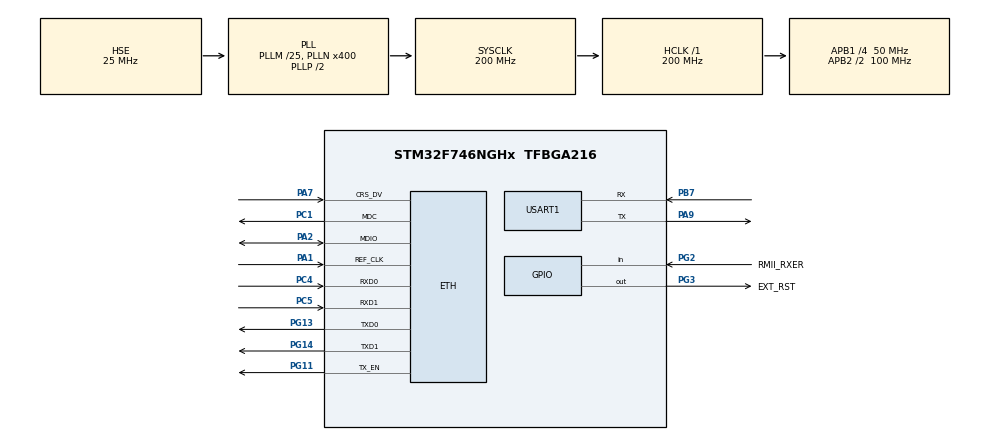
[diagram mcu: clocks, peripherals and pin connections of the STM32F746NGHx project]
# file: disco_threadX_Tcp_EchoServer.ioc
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ETH.MACAddr=00\:80\:E1\:00\:00\:01
ETH.MediaInterface=HAL_ETH_RMII_MODE
Mcu.Family=STM32F7
Mcu.Name=STM32F746NGHx
Mcu.Package=TFBGA216
NVIC.ETH_IRQn=true\:0\:0\:false\:false\:true\:false\:true\:true\:true
NVIC.ETH_WKUP_IRQn=true\:0\:0\:false\:false\:true\:false\:true\:true\:true
NVIC.PriorityGroup=NVIC_PRIORITYGROUP_4
NVIC.TIM6_DAC_IRQn=true\:15\:0\:false\:false\:true\:false\:false\:true\:true
NVIC.TimeBase=TIM6_DAC_IRQn
NVIC.TimeBaseIP=TIM6
PA1.Mode=RMII
PA1.Signal=ETH_REF_CLK
PA13.Mode=Serial_Wire
PA13.Signal=SYS_JTMS-SWDIO
PA14.Mode=Serial_Wire
PA14.Signal=SYS_JTCK-SWCLK
PA2.Mode=RMII
PA2.Signal=ETH_MDIO
PA7.Mode=RMII
PA7.Signal=ETH_CRS_DV
PA9.Mode=Asynchronous
PA9.Signal=USART1_TX
PB7.Mode=Asynchronous
PB7.Signal=USART1_RX
PC1.Mode=RMII
PC1.Signal=ETH_MDC
PC14/OSC32_IN.Mode=LSE-External-Oscillator
PC14/OSC32_IN.Signal=RCC_OSC32_IN
PC15/OSC32_OUT.Mode=LSE-External-Oscillator
PC15/OSC32_OUT.Signal=RCC_OSC32_OUT
PC4.Mode=RMII
PC4.Signal=ETH_RXD0
PC5.Mode=RMII
PC5.Signal=ETH_RXD1
PG11.Mode=RMII
PG11.Signal=ETH_TX_EN
PG13.Mode=RMII
PG13.Signal=ETH_TXD0
PG14.Mode=RMII
PG14.Signal=ETH_TXD1
PG2.GPIO_Label=RMII_RXER
PG2.Signal=GPIO_Input
PG3.GPIO_Label=EXT_RST
PG3.Signal=GPIO_Output
PH0/OSC_IN.Mode=HSE-External-Oscillator
PH0/OSC_IN.Signal=RCC_OSC_IN
PH1/OSC_OUT.Mode=HSE-External-Oscillator
PH1/OSC_OUT.Signal=RCC_OSC_OUT
ProjectManager.HeapSize=0x200
ProjectManager.StackSize=0x400
ProjectManager.TargetToolchain=STM32CubeIDE
RCC.AHBFreq_Value=200000000
RCC.APB1CLKDivider=RCC_HCLK_DIV4
RCC.APB1Freq_Value=50000000
RCC.APB1TimFreq_Value=100000000
RCC.APB2CLKDivider=RCC_HCLK_DIV2
RCC.APB2Freq_Value=100000000
RCC.APB2TimFreq_Value=200000000
RCC.CortexFreq_Value=200000000
RCC.HCLKFreq_Value=200000000
RCC.HSE_VALUE=25000000
RCC.HSI_VALUE=16000000
RCC.PLL48CLockSelection=RCC_CLK48SOURCE_PLLSAIP
RCC.PLLI2SN=100
RCC.PLLM=25
RCC.PLLN=400
RCC.PLLQ=9
RCC.PLLSAIN=384
RCC.PLLSAIP=RCC_PLLSAIP_DIV8
RCC.PLLSAIR=5
RCC.PLLSAIRDiv=RCC_PLLSAIDIVR_8
RCC.PLLSourceVirtual=RCC_PLLSOURCE_HSE
RCC.SDMMCClockSelection=RCC_SDMMC1CLKSOURCE_CLK48
RCC.SYSCLKFreq_VALUE=200000000
RCC.SYSCLKSource=RCC_SYSCLKSOURCE_PLLCLK
RCC.USBFreq_Value=48000000
RCC.VCOOutputFreq_Value=400000000
STMicroelectronics.X-CUBE-AZRTOS-F7.1.1.0.InterfacesCcNetworkJjEthernetOoInterface=true
STMicroelectronics.X-CUBE-AZRTOS-F7.1.1.0.InterfacesCcNetworkJjEthernetOoPhyOoInterface=LAN8742IiPhyIiInterface
STMicroelectronics.X-CUBE-AZRTOS-F7.1.1.0.NX_ENABLE_INTERFACE_CAPABILITY=true
STMicroelectronics.X-CUBE-AZRTOS-F7.1.1.0.NetXDuoCcNetworkJjNetXDuoJjAddonsOoDHCPOoClient=true
STMicroelectronics.X-CUBE-AZRTOS-F7.1.1.0.NetXDuoCcNetworkJjNetXDuoJjNXOoCore=true
STMicroelectronics.X-CUBE-AZRTOS-F7.1.1.0.STM32CubeIiBSPIiComponentsCcBoardOoPartJjETHPhyJjLAN8742=true
STMicroelectronics.X-CUBE-AZRTOS-F7.1.1.0.ThreadXCcRTOSJjThreadXJjCore=true
STMicroelectronics.X-CUBE-AZRTOS-F7.1.1.0_IsAnAzureRtosMw=true
USART1.VirtualMode-Asynchronous=VM_ASYNC
VP_CRC_VS_CRC.Mode=CRC_Activate
VP_STMicroelectronics.X-CUBE-AZRTOS-F7_VS_BoardOoPartJjSTM32CubeIiBSPIiComponents_1.1.0_1.1.0.Mode=BoardOoPartJjSTM32CubeIiBSPIiComponents
VP_STMicroelectronics.X-CUBE-AZRTOS-F7_VS_NetworkJjInterfaces_2.1.0_1.1.0.Mode=NetworkJjInterfaces
VP_STMicroelectronics.X-CUBE-AZRTOS-F7_VS_NetworkJjNetXDuo_6.1.10_1.1.0.Mode=NetworkJjNetXDuo
VP_STMicroelectronics.X-CUBE-AZRTOS-F7_VS_RTOSJjThreadX_6.1.10_1.1.0.Mode=RTOSJjThreadX
VP_SYS_VS_tim6.Mode=TIM6
board=STM32F746G-DISCO

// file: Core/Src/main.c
/* USER CODE BEGIN Header */
/**
  ******************************************************************************
  * @file           : main.c
  * @brief          : Main program body
  ******************************************************************************
  * @attention
  *
  * Copyright (c) 2025 STMicroelectronics.
  * All rights reserved.
  *
  * This software is licensed under terms that can be found in the LICENSE file
  * in the root directory of this software component.
  * If no LICENSE file comes with this software, it is provided AS-IS.
  *
  ******************************************************************************
  */
/* USER CODE END Header */
#include "app_threadx.h"
#include "main.h"
#include "string.h"

/* USER CODE BEGIN Includes */
#include <stdio.h>

/* USER CODE END Includes */

ETH_TxPacketConfig TxConfig;
ETH_DMADescTypeDef  DMARxDscrTab[ETH_RX_DESC_CNT]; /* Ethernet Rx DMA Descriptors */
ETH_DMADescTypeDef  DMATxDscrTab[ETH_TX_DESC_CNT]; /* Ethernet Tx DMA Descriptors */

CRC_HandleTypeDef hcrc;

ETH_HandleTypeDef heth;

UART_HandleTypeDef huart1;

void SystemClock_Config(void);
static void MX_GPIO_Init(void);
static void MX_USART1_UART_Init(void);
static void MX_CRC_Init(void);
static void MX_ETH_Init(void);

/* USER CODE BEGIN 0 */
int _write(int file, char *ptr, int len) {
    for (int i = 0; i < len; i++) {
        HAL_UART_Transmit(&huart1, (uint8_t *)&ptr[i], 1, HAL_MAX_DELAY);
    }
    return len;
}

/* USER CODE END 0 */

int main(void)
{

  /* MCU Configuration--------------------------------------------------------*/

  /* Reset of all peripherals, Initializes the Flash interface and the Systick. */
  HAL_Init();

  /* Configure the system clock */
  SystemClock_Config();

  /* Initialize all configured peripherals */
  MX_GPIO_Init();
  MX_USART1_UART_Init();
  MX_CRC_Init();
  MX_ETH_Init();
  /* USER CODE BEGIN 2 */
  setvbuf(stdout, NULL, _IONBF, 0);

  /* USER CODE END 2 */

  MX_ThreadX_Init();

  /* We should never get here as control is now taken by the scheduler */

  /* Infinite loop */
  while (1)
  {

  }
}

void SystemClock_Config(void)
{
  RCC_OscInitTypeDef RCC_OscInitStruct = {0};
  RCC_ClkInitTypeDef RCC_ClkInitStruct = {0};

  /** Configure LSE Drive Capability
  */
  HAL_PWR_EnableBkUpAccess();

  /** Configure the main internal regulator output voltage
  */
  __HAL_RCC_PWR_CLK_ENABLE();
  __HAL_PWR_VOLTAGESCALING_CONFIG(PWR_REGULATOR_VOLTAGE_SCALE1);

  /** Initializes the RCC Oscillators according to the specified parameters
  * in the RCC_OscInitTypeDef structure.
  */
  RCC_OscInitStruct.OscillatorType = RCC_OSCILLATORTYPE_HSE;
  RCC_OscInitStruct.HSEState = RCC_HSE_ON;
  RCC_OscInitStruct.PLL.PLLState = RCC_PLL_ON;
  RCC_OscInitStruct.PLL.PLLSource = RCC_PLLSOURCE_HSE;
  RCC_OscInitStruct.PLL.PLLM = 25;
  RCC_OscInitStruct.PLL.PLLN = 400;
  RCC_OscInitStruct.PLL.PLLP = RCC_PLLP_DIV2;
  RCC_OscInitStruct.PLL.PLLQ = 9;
  if (HAL_RCC_OscConfig(&RCC_OscInitStruct) != HAL_OK)
  {
    Error_Handler();
  }

  /** Activate the Over-Drive mode
  */
  if (HAL_PWREx_EnableOverDrive() != HAL_OK)
  {
    Error_Handler();
  }

  /** Initializes the CPU, AHB and APB buses clocks
  */
  RCC_ClkInitStruct.ClockType = RCC_CLOCKTYPE_HCLK|RCC_CLOCKTYPE_SYSCLK
                              |RCC_CLOCKTYPE_PCLK1|RCC_CLOCKTYPE_PCLK2;
  RCC_ClkInitStruct.SYSCLKSource = RCC_SYSCLKSOURCE_PLLCLK;
  RCC_ClkInitStruct.AHBCLKDivider = RCC_SYSCLK_DIV1;
  RCC_ClkInitStruct.APB1CLKDivider = RCC_HCLK_DIV4;
  RCC_ClkInitStruct.APB2CLKDivider = RCC_HCLK_DIV2;

  if (HAL_RCC_ClockConfig(&RCC_ClkInitStruct, FLASH_LATENCY_6) != HAL_OK)
  {
    Error_Handler();
  }
}

static void MX_CRC_Init(void)
{

  hcrc.Instance = CRC;
  hcrc.Init.DefaultPolynomialUse = DEFAULT_POLYNOMIAL_ENABLE;
  hcrc.Init.DefaultInitValueUse = DEFAULT_INIT_VALUE_ENABLE;
  hcrc.Init.InputDataInversionMode = CRC_INPUTDATA_INVERSION_NONE;
  hcrc.Init.OutputDataInversionMode = CRC_OUTPUTDATA_INVERSION_DISABLE;
  hcrc.InputDataFormat = CRC_INPUTDATA_FORMAT_BYTES;
  if (HAL_CRC_Init(&hcrc) != HAL_OK)
  {
    Error_Handler();
  }

}

static void MX_ETH_Init(void)
{

   static uint8_t MACAddr[6];

  heth.Instance = ETH;
  MACAddr[0] = 0x00;
  MACAddr[1] = 0x80;
  MACAddr[2] = 0xE1;
  MACAddr[3] = 0x00;
  MACAddr[4] = 0x00;
  MACAddr[5] = 0x01;
  heth.Init.MACAddr = &MACAddr[0];
  heth.Init.MediaInterface = HAL_ETH_RMII_MODE;
  heth.Init.TxDesc = DMATxDscrTab;
  heth.Init.RxDesc = DMARxDscrTab;
  heth.Init.RxBuffLen = 1536;

  if (HAL_ETH_Init(&heth) != HAL_OK)
  {
    Error_Handler();
  }

  memset(&TxConfig, 0 , sizeof(ETH_TxPacketConfig));
  TxConfig.Attributes = ETH_TX_PACKETS_FEATURES_CSUM | ETH_TX_PACKETS_FEATURES_CRCPAD;
  TxConfig.ChecksumCtrl = ETH_CHECKSUM_IPHDR_PAYLOAD_INSERT_PHDR_CALC;
  TxConfig.CRCPadCtrl = ETH_CRC_PAD_INSERT;

}

static void MX_USART1_UART_Init(void)
{

  huart1.Instance = USART1;
  huart1.Init.BaudRate = 115200;
  huart1.Init.WordLength = UART_WORDLENGTH_8B;
  huart1.Init.StopBits = UART_STOPBITS_1;
  huart1.Init.Parity = UART_PARITY_NONE;
  huart1.Init.Mode = UART_MODE_TX_RX;
  huart1.Init.HwFlowCtl = UART_HWCONTROL_NONE;
  huart1.Init.OverSampling = UART_OVERSAMPLING_16;
  huart1.Init.OneBitSampling = UART_ONE_BIT_SAMPLE_DISABLE;
  huart1.AdvancedInit.AdvFeatureInit = UART_ADVFEATURE_NO_INIT;
  if (HAL_UART_Init(&huart1) != HAL_OK)
  {
    Error_Handler();
  }

}

static void MX_GPIO_Init(void)
{
  GPIO_InitTypeDef GPIO_InitStruct = {0};

  /* GPIO Ports Clock Enable */
  __HAL_RCC_GPIOG_CLK_ENABLE();
  __HAL_RCC_GPIOA_CLK_ENABLE();
  __HAL_RCC_GPIOB_CLK_ENABLE();
  __HAL_RCC_GPIOC_CLK_ENABLE();
  __HAL_RCC_GPIOH_CLK_ENABLE();

  /*Configure GPIO pin Output Level */
  HAL_GPIO_WritePin(EXT_RST_GPIO_Port, EXT_RST_Pin, GPIO_PIN_RESET);

  /*Configure GPIO pin : EXT_RST_Pin */
  GPIO_InitStruct.Pin = EXT_RST_Pin;
  GPIO_InitStruct.Mode = GPIO_MODE_OUTPUT_PP;
  GPIO_InitStruct.Pull = GPIO_NOPULL;
  GPIO_InitStruct.Speed = GPIO_SPEED_FREQ_LOW;
  HAL_GPIO_Init(EXT_RST_GPIO_Port, &GPIO_InitStruct);

  /*Configure GPIO pin : RMII_RXER_Pin */
  GPIO_InitStruct.Pin = RMII_RXER_Pin;
  GPIO_InitStruct.Mode = GPIO_MODE_INPUT;
  GPIO_InitStruct.Pull = GPIO_NOPULL;
  HAL_GPIO_Init(RMII_RXER_GPIO_Port, &GPIO_InitStruct);

}

/* USER CODE BEGIN 4 */
/**
* @brief  This function is executed in case of success.
* @retval None
*/
void Success_Handler(void)
{
  /* USER CODE BEGIN Success_Handler_Debug */
  HAL_GPIO_WritePin(GPIOB, GPIO_PIN_14, GPIO_PIN_RESET);
  while (1)
  {
    HAL_GPIO_TogglePin(GPIOB, GPIO_PIN_0);
    HAL_Delay(200);
  }
  /* USER CODE END Success_Handler_Debug */
}
/* USER CODE END 4 */

void HAL_TIM_PeriodElapsedCallback(TIM_HandleTypeDef *htim)
{
  if (htim->Instance == TIM6) {
    HAL_IncTick();
  }
}

void Error_Handler(void)
{
  __disable_irq();
  while (1)
  {
  }
}
